# ICSSM_ICSSM_PR1_ICSS_ECAP0_ECAP_SLV_48030000h register map
Vendor: Texas Instruments
Peripheral module from a debugger description file (folder AM261x).
Registers are 32-bit, read-write, reset 0x0 unless marked. A register's access mark holds for its fields unless they carry their own. Offsets are as the file gives them; lines under a group give offsets from that group; [hi:lo] are bit positions; {n}, {i} and the like mark numbered series; 'fields as' and 'values as' point back to an identical list; <NAME> marks a mode.

## ICSSM_PR1_ICSS_ECAP0_ECAP_SLV
0x00 ICSSM_PR1_ICSS_ECAP0_ECAP_SLV_TSCNT — TIME STAMP COUNTER REGISTER.
  [31:0] TSCNT — ACTIVE 32 BIT COUNTER REGISTER WHICH IS USED AS THE CAPTURE TIME-BASE
0x04 ICSSM_PR1_ICSS_ECAP0_ECAP_SLV_CNTPHS — COUNTER PHASE CONTROL REGISTER.
  [31:0] CNTPHS — COUNTER PHASE VALUE REGISTER THAT CAN BE PROGRAMMED FOR PHASE LAG/LEAD THIS REGISTER SHADOWS TSCNT AND IS LOADED INTO TSCNT UPON EITHER A SYNCI EVENT OR S/W FORCE VIA A CONTROL BITUSED TO ACHIEVE PHASE CONTROL SYNC WITH RESPECT TO OTHER ECAP AND EPWM TIME-BASES
0x08 ICSSM_PR1_ICSS_ECAP0_ECAP_SLV_CAP1 — CAPTURE-1 REGISTER.
  [31:0] CAP1 — THIS REGISTER CAN BE LOADED [WRITTEN] BY :TIME-STAMP [IE COUNTER VALUE] DURING A CAPTURE EVENTS/W MAY BE USEFUL FOR TEST PURPOSES / INITIALISATIONAPRD SHADOW REGISTER [IE CAP3] WHEN USED IN APWM MODE
0x0C ICSSM_PR1_ICSS_ECAP0_ECAP_SLV_CAP2 — CAPTURE-2 REGISTER.
  [31:0] CAP2 — THIS REGISTER CAN BE LOADED [WRITTEN] BY :TIME-STAMP [IE COUNTER VALUE] DURING A CAPTURE EVENTS/W MAY BE USEFUL FOR TEST PURPOSESACMP SHADOW REGISTER [IE CAP4] WHEN USED IN APWM MODE
0x10 ICSSM_PR1_ICSS_ECAP0_ECAP_SLV_CAP3 — CAPTURE-3 REGISTER.
  [31:0] CAP3 — IN CMP MODE THIS IS A TIME-STAMP CAPTURE REGISTERIN APMW MODE THIS IS THE PERIOD SHADOW [APER] REGISTER USER UPDATES THE PWM PERIOD VALUE VIA THIS REGISTER IN THIS MODE CAP3 [APRD] SHADOWS CAP1
0x14 ICSSM_PR1_ICSS_ECAP0_ECAP_SLV_CAP4 — CAPTURE-4 REGISTER.
  [31:0] CAP4 — IN CMP MODE THIS IS A TIME-STAMP CAPTURE REGISTERIN APMW MODE THIS IS THE COMPARE SHADOW [ACMP] REGISTER USER UPDATES THE PWM COMPARE VALUE VIA THIS REGISTER IN THIS MODE CAP4 [ACMP] SHADOWS CAP2
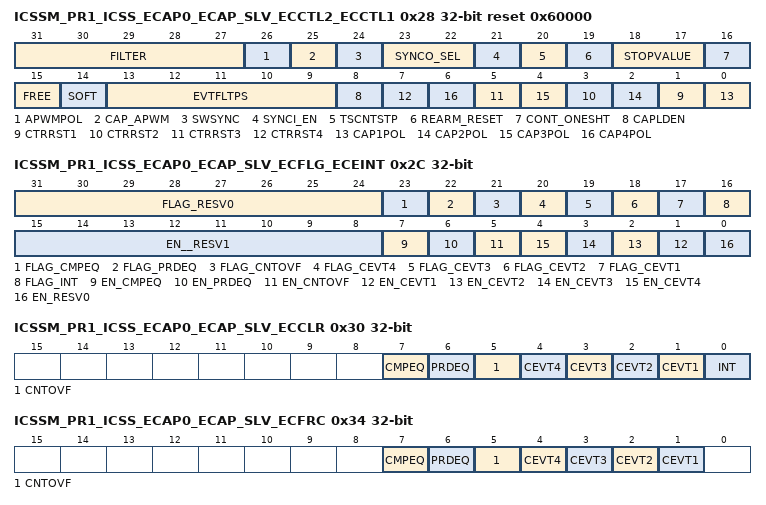
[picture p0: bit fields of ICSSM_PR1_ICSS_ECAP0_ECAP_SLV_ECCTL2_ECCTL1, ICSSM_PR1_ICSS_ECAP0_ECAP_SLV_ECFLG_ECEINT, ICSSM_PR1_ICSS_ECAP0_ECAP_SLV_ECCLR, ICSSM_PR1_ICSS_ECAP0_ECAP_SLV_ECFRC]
0x28 ICSSM_PR1_ICSS_ECAP0_ECAP_SLV_ECCTL2_ECCTL1 access per field reset 0x60000 — ECAP CONTROL REGISTER 1
  [31:27] FILTER ro
  [26] APWMPOL rw — APWM OUTPUT POLARITY SELECT:0OUTPUT IS ACTIVE HIGH [IE COMPARE VALUE DEFINES HIGH TIME]1OUTPUT IS ACTIVE LOW [IE COMPARE VALUE DEFINES LOW TIME]NOTE: THIS IS APPLICABLE ONLY IN APWM OPERATING MODE
  [25] CAP_APWM rw — CAP/APWM OPERATING MODE SELECT:0ECAP MODULE OPERATES IN CAPTURE MODETHIS MODE FORCES THE FOLLOWING CONFIGURATION:1] INHIBITS TSCNT RESETS VIA PRD_EQ EVENT2] INHIBITS SHADOW LOADS ON CAP1 &
  [24] SWSYNC rw — SOFTWARE FORCED COUNTER [TSCNT] SYNCING:0WRITING A ZERO HAS NO EFFECT WILL ALWAYS RETURN A ZERO1WRITING A ONE WILL FORCE A TSCNT SHADOW LOAD OF CURRENT ECAP MODULE AND ANY ECAP MODULES DOWN-STREAM PROVIDING THE SYNCO_SEL BITS ARE 0,0 AFTER WRITING A ONE THIS BIT RETURNS TO A ZERONOTE: THIS PROVIDES A CONVENIENT S/W METHOD TO SYNCHRONIZE SOME OR ALL ECAP TIMEBASES IN APWM MODE THE SYNCING CAN ALSO BE DONE VIA THE PRD_EQ EVENT
  [23:22] SYNCO_SEL rw — SYNC-OUT SELECT:0,0SELECT SYNC-IN EVENT TO BE THE SYNC-OUT SIGNAL [PASS THROUGH]0,1SELECT PRD_EQ EVENT TO BE THE SYNC-OUT SIGNAL1,0DISABLE SYNC OUT SIGNAL1,1DISABLE SYNC OUT SIGNALNOTE: SELECTION PRD_EQ IS MEANINGFUL ONLY IN APWM MODE, HOWEVER CAN STILL BE CHOSEN IN CAP MODE IF USER BELIEVES IT TO BE USEFUL
  [21] SYNCI_EN rw — COUNTER [TSCNT] SYNC-IN SELECT MODE:0DISABLE SYNC-IN OPTION1ENABLE COUNTER [TSCNT] TO BE LOADED FROM CNTPHS REGISTER UPON EITHER A SYNCI SIGNAL OR A S/W FORCE EVENT
  [20] TSCNTSTP rw — COUNTER STOP [FREEZE] CONTROL:0COUNTER STOPPED1COUNTER FREE RUNNING
  [19] REARM_RESET rw — ONE-SHOT RE-ARMING, IE WAIT FOR STOP TRIGGER:WRITING A ONE ARMS THE ONE-SHOT SEQUENCE, IE:1] RESETS THE MOD4 COUNTER TO ZERO2] UN-FREEZES THE MOD4 COUNTER3] ENABLES CAPTURE REGISTER LOADSWRITING A ZERO HAS NO EFFECT ALWAYS RETURNS A 0NOTE: THE RE-ARM FUNCTION IS VALID IN ONESHT OR CONTINOUS MODE
  [18:17] STOPVALUE rw — STOP VALUE FOR ONE-SHOT MODE:THIS IS THE NUMBER [BETWEEN 1-4] OF CAPTURES ALLOWED TO OCCUR BEFORE THE CAP[1-4] REGISTERS ARE FROZEN, IECAPTURE SEQUENCE IS STOPPED0,0STOP AFTER CAPTURE EVENT 10,1STOP AFTER CAPTURE EVENT 21,0STOP AFTER CAPTURE EVENT 31,1STOP AFTER CAPTURE EVENT 4NOTES: [1] STOPVALUE IS COMPARED TO MOD4 COUNTER, WHEN EQUAL, 2 ACTIONS OCCUR:1] MOD4 COUNTER IS STOPPED [FROZEN]2] CAPTURE REGISTER LOADS ARE INHIBITED[2] IN ONE SHOT MODE, FURTHER INTERRUPT EVENTS ARE BLOCKED UNTIL WE RE-ARM, ONCE THE NUMBER OF EVENTS CAPTURED HAS BEEN REACHED
  [16] CONT_ONESHT rw — CONTINUOUS OR ONESHOT MODE CONTROL:[APPLICABLE ONLY IN CAPTURE MODE]0OPERATE IN CONTINUOUS MODE1OPERATE IN ONE-SHOT MODE
  [15] FREE rw — EMULATION CONTROL0,0 TSCNT COUNTER STOPS IMMEDIATELY ON EMULATION SUSPEND0,1 TSCNT COUNTER RUNS UNTIL = 01,X TSCNT COUNTER IS UNAFFECTED BY EMULATION SUSPEND [RUN FREE]
  [14] SOFT rw — EMULATION CONTROL0,0 TSCNT COUNTER STOPS IMMEDIATELY ON EMULATION SUSPEND0,1 TSCNT COUNTER RUNS UNTIL = 01,X TSCNT COUNTER IS UNAFFECTED BY EMULATION SUSPEND [RUN FREE]
  [13:9] EVTFLTPS rw — EVENT FILTER PRESCALE SELECT:0,0,0,0,0DIVIDE BY 1 [IE NO PRESCALE, BY-PASS THE PRESCALER]0,0,0,0,1DIVIDE BY 20,0,0,1,0DIVIDE BY 40,0,0,1,1DIVIDE BY 60,0,1,0,0DIVIDE BY 80,0,1,0,1DIVIDE BY 10 1,1,1,1,0DIVIDE BY 601,1,1,1,1DIVIDE BY 62
  [8] CAPLDEN rw — ENABLE LOADING OF CAP1-4 REGISTERS ON A CAPTURE EVENT:0DISABLE CAP1-4 REGISTER LOADS AT CAPTURE EVENT TIME1ENABLE CAP1-4 REGISTER LOADS AT CAPTURE EVENT TIME
  [2n-1] CTRRST{n} rw (n=1..4) — COUNTER RESET ON CAPTURE EVENT {n}:0DO NOT RESET COUNTER ON CAPTURE EVENT {n} [ABSOLUTE TIME STAMP]1RESET COUNTER AFTER EVENT {n} TIME-STAMP HAS BEEN CAPTURED[USED IN DIFFERENCE MODE OPERATION]
  [2n-2] CAP{n}POL rw (n=1..4) — CAPTURE EVENT {n} POLARITY SELECT:0CAPTURE EVENT {n} TRIGGERED ON A RISING EDGE [FE]1CAPTURE EVENT {n} TRIGGERED ON A FALLING EDGE [FE]
0x2C ICSSM_PR1_ICSS_ECAP0_ECAP_SLV_ECFLG_ECEINT access per field — ECAP INTERRUPT ENABLE REGISTER.
  [31:24] FLAG_RESV0 ro
  [23] FLAG_CMPEQ ro — COMPARE EQUAL STATUS FLAG: READING A 1 ON THIS BIT INDICATES THE COUNTER [TSCNT] REACHED THE COMPARE REGISTER VALUE [ACMP]READING A 0 INDICATES NO EVENT OCCURREDNOTE: THIS FLAG IS ONLY ACTIVE IN APWM MODE
  [22] FLAG_PRDEQ ro — PERIOD EQUAL STATUS FLAG: READING A 1 ON THIS BIT INDICATES THE COUNTER [TSCNT] REACHED THE PERIOD REGISTER VALUE [APER] AND WAS RESETREADING A 0 INDICATES NO EVENT OCCURREDNOTES: THIS FLAG IS ONLY ACTIVE IN APWM MODE
  [21] FLAG_CNTOVF ro — COUNTER OVERFLOW STATUS FLAG: READING A 1 ON THIS BIT INDICATES THE COUNTER [TSCNT] HAS MADE THE TRANSITION FROM FFFFFFFF 00000000READING A 0 INDICATES NO EVENT OCCURREDNOTE: THIS FLAG IS ACTIVE IN CAP &
  [20] FLAG_CEVT4 ro — CAPTURE EVENT 4 STATUS FLAG: READING A 1 ON THIS BIT INDICATES THE FOURTH EVENT OCCURRED AT ECAPX PINREADING A 0 INDICATES NO EVENT OCCURREDNOTE: THIS FLAG IS ONLY ACTIVE IN CAP MODE
  [19] FLAG_CEVT3 ro — CAPTURE EVENT 3 STATUS FLAG: READING A 1 ON THIS BIT INDICATES THE THIRD EVENT OCCURRED AT ECAPX PINREADING A 0 INDICATES NO EVENT OCCURREDNOTE: THIS FLAG IS ONLY ACTIVE IN CAP MODE
  [18] FLAG_CEVT2 ro — CAPTURE EVENT 2 STATUS FLAG: READING A 1 ON THIS BIT INDICATES THE SECOND EVENT OCCURRED AT ECAPX PINREADING A 0 INDICATES NO EVENT OCCURREDNOTE: THIS FLAG IS ONLY ACTIVE IN CAP MODE
  [17] FLAG_CEVT1 ro — CAPTURE EVENT 1 STATUS FLAG: READING A 1 ON THIS BIT INDICATES THE FIRST EVENT OCCURRED AT ECAPX PINREADING A 0 INDICATES NO EVENT OCCURREDNOTE: THIS FLAG IS ONLY ACTIVE IN CAP MODE
  [16] FLAG_INT ro — GLOBAL INTERRUPT STATUS FLAG: READING A 1 ON THIS BIT INDICATES THAT AN INTERRUPT WAS GENERATED FROM ONE OF THE FOLLOWING EVENTSREADING A 0 INDICATES NO INTERRUPT GENERATED
  [15:8] EN__RESV1 ro
  [7] EN_CMPEQ rw — COMPARE EQUAL INTERRUPT ENABLE: 0DISABLED COMPARE EQUAL AS AN INTERRUPT SOURCE1ENABLE COMPARE EQUAL AS AN INTERRUPT SOURCE
  [6] EN_PRDEQ rw — PERIOD EQUAL INTERRUPT ENABLE: 0DISABLED PERIOD EQUAL AS AN INTERRUPT SOURCE1ENABLE PERIOD EQUAL AS AN INTERRUPT SOURCE
  [5] EN_CNTOVF rw — COUNTER OVERFLOW INTERRUPT ENABLE: 0DISABLED COUNTER OVERFLOW AS AN INTERRUPT SOURCE1ENABLE COUNTER OVERFLOW AS AN INTERRUPT SOURCE
  [n] EN_CEVT{n} rw (n=1..4) — CAPTURE EVENT {n} INTERRUPT ENABLE: 0DISABLED CAPTURE EVENT 1 AS AN INTERRUPT SOURCE1ENABLE CAPTURE EVENT 1 AS AN INTERRUPT SOURCE
  [0] EN_RESV0 ro
0x30 ICSSM_PR1_ICSS_ECAP0_ECAP_SLV_ECCLR access per field — ECAP INTERRUPT CLEAR REGISTER.
  [7] CMPEQ rw — COMPARE EQUAL STATUS FLAG: WRITING A 1 WILL CLEAR THE CMPEQ FLAG CONDITIONWRITING A 0 WILL HAVE NO EFFECTALWAYS READS BACK A 0
  [6] PRDEQ rw — PERIOD EQUAL STATUS FLAG: WRITING A 1 WILL CLEAR THE PRDEQ FLAG CONDITIONWRITING A 0 WILL HAVE NO EFFECTALWAYS READS BACK A 0
  [5] CNTOVF rw — COUNTER OVERFLOW STATUS FLAG: WRITING A 1 WILL CLEAR THE CNTOVF FLAG CONDITIONWRITING A 0 WILL HAVE NO EFFECTALWAYS READS BACK A 0
  [4] CEVT4 rw — CAPTURE EVENT 4 STATUS FLAG: WRITING A 1 WILL CLEAR THE CEVT3 FLAG CONDITIONWRITING A 0 WILL HAVE NO EFFECTALWAYS READS BACK A 0
  [3] CEVT3 rw — CAPTURE EVENT 3 STATUS FLAG: WRITING A 1 WILL CLEAR THE CEVT3 FLAG CONDITIONWRITING A 0 WILL HAVE NO EFFECTALWAYS READS BACK A 0
  [2] CEVT2 rw — CAPTURE EVENT 2 STATUS FLAG: WRITING A 1 WILL CLEAR THE CEVT2 FLAG CONDITIONWRITING A 0 WILL HAVE NO EFFECTALWAYS READS BACK A 0
  [1] CEVT1 rw — CAPTURE EVENT 1 STATUS FLAG: WRITING A 1 WILL CLEAR THE CEVT1 FLAG CONDITIONWRITING A 0 WILL HAVE NO EFFECTALWAYS READS BACK A 0
  [0] INT rw — GLOBAL INTERRUPT CLEAR FLAG: WRITING A 1 WILL CLEAR THE INT FLAG AND ENABLE FURTHER INTERRUPTS TO BE GENERATED IF ANY OF THE EVENT FLAGS ARE SET TO 1WRITING A 0 WILL HAVE NO EFFECTALWAYS READS BACK A 0
0x34 ICSSM_PR1_ICSS_ECAP0_ECAP_SLV_ECFRC access per field — ECAP INTERRUPT FORCING REGISTER.
  [7] CMPEQ rw — FORCE COMPARE EQUAL: WRITING A 1 TO THIS BIT WILL SET THE CMPEQ FLAG BITWRITING OF 0 WILL BE IGNORED ALWAYS READS BACK A 0
  [6] PRDEQ rw — FORCE PERIOD EQUAL: WRITING A 1 TO THIS BIT WILL SET THE PRDEQ FLAG BITWRITING OF 0 WILL BE IGNORED ALWAYS READS BACK A 0
  [5] CNTOVF rw — FORCE COUNTER OVERFLOW: WRITING A 1 TO THIS BIT WILL SET THE CNTOVF FLAG BITWRITING OF 0 WILL BE IGNORED ALWAYS READS BACK A 0
  [n] CEVT{n} rw (n=1..4) — FORCE CAPTURE EVENT{n}:WRITING A 1 TO THIS BIT WILL SET THE CEVT{n} FLAG BITWRITING OF 0 WILL BE IGNORED ALWAYS READS BACK A 0
0x5C ICSSM_PR1_ICSS_ECAP0_ECAP_SLV_REVID1 ro reset 0x44D22100 — Revision Identification Register 1
  [31:0] REVID
